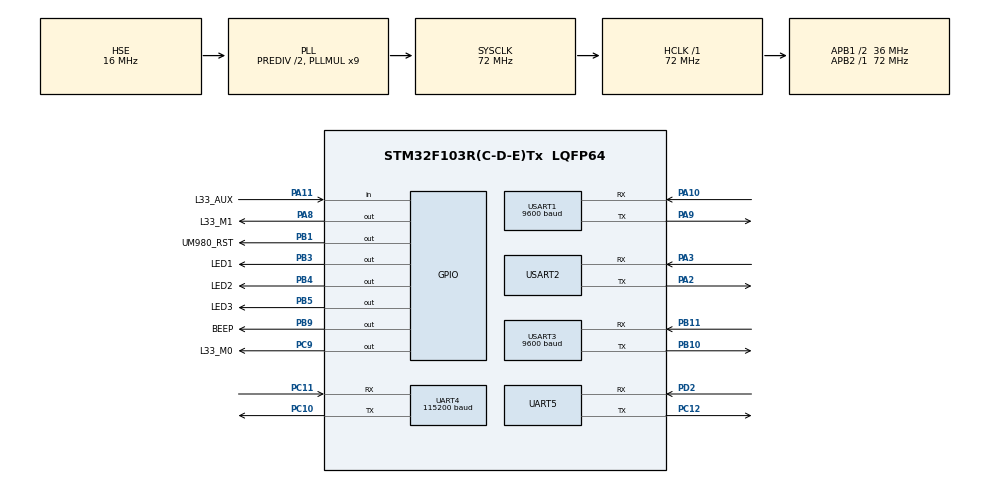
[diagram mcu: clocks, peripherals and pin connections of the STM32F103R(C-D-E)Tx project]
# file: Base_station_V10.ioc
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Dma.Request0=USART1_RX
Dma.Request1=USART1_TX
Dma.Request2=USART2_RX
Dma.Request3=USART2_TX
Dma.Request4=USART3_RX
Dma.Request5=USART3_TX
Dma.Request6=UART4_RX
Dma.Request7=UART4_TX
Dma.UART4_RX.6.Direction=DMA_PERIPH_TO_MEMORY
Dma.UART4_RX.6.Instance=DMA2_Channel3
Dma.UART4_RX.6.MemDataAlignment=DMA_MDATAALIGN_BYTE
Dma.UART4_RX.6.MemInc=DMA_MINC_ENABLE
Dma.UART4_RX.6.Mode=DMA_NORMAL
Dma.UART4_RX.6.PeriphDataAlignment=DMA_PDATAALIGN_BYTE
Dma.UART4_RX.6.PeriphInc=DMA_PINC_DISABLE
Dma.UART4_RX.6.Priority=DMA_PRIORITY_LOW
Dma.UART4_TX.7.Direction=DMA_MEMORY_TO_PERIPH
Dma.UART4_TX.7.Instance=DMA2_Channel5
Dma.UART4_TX.7.MemDataAlignment=DMA_MDATAALIGN_BYTE
Dma.UART4_TX.7.MemInc=DMA_MINC_ENABLE
Dma.UART4_TX.7.Mode=DMA_NORMAL
Dma.UART4_TX.7.PeriphDataAlignment=DMA_PDATAALIGN_BYTE
Dma.UART4_TX.7.PeriphInc=DMA_PINC_DISABLE
Dma.UART4_TX.7.Priority=DMA_PRIORITY_LOW
Dma.USART1_RX.0.Direction=DMA_PERIPH_TO_MEMORY
Dma.USART1_RX.0.Instance=DMA1_Channel5
Dma.USART1_RX.0.MemDataAlignment=DMA_MDATAALIGN_BYTE
Dma.USART1_RX.0.MemInc=DMA_MINC_ENABLE
Dma.USART1_RX.0.Mode=DMA_NORMAL
Dma.USART1_RX.0.PeriphDataAlignment=DMA_PDATAALIGN_BYTE
Dma.USART1_RX.0.PeriphInc=DMA_PINC_DISABLE
Dma.USART1_RX.0.Priority=DMA_PRIORITY_MEDIUM
Dma.USART1_TX.1.Direction=DMA_MEMORY_TO_PERIPH
Dma.USART1_TX.1.Instance=DMA1_Channel4
Dma.USART1_TX.1.MemDataAlignment=DMA_MDATAALIGN_BYTE
Dma.USART1_TX.1.MemInc=DMA_MINC_ENABLE
Dma.USART1_TX.1.Mode=DMA_NORMAL
Dma.USART1_TX.1.PeriphDataAlignment=DMA_PDATAALIGN_BYTE
Dma.USART1_TX.1.PeriphInc=DMA_PINC_DISABLE
Dma.USART1_TX.1.Priority=DMA_PRIORITY_LOW
Dma.USART2_RX.2.Direction=DMA_PERIPH_TO_MEMORY
Dma.USART2_RX.2.Instance=DMA1_Channel6
Dma.USART2_RX.2.MemDataAlignment=DMA_MDATAALIGN_BYTE
Dma.USART2_RX.2.MemInc=DMA_MINC_ENABLE
Dma.USART2_RX.2.Mode=DMA_NORMAL
Dma.USART2_RX.2.PeriphDataAlignment=DMA_PDATAALIGN_BYTE
Dma.USART2_RX.2.PeriphInc=DMA_PINC_DISABLE
Dma.USART2_RX.2.Priority=DMA_PRIORITY_LOW
Dma.USART2_TX.3.Direction=DMA_MEMORY_TO_PERIPH
Dma.USART2_TX.3.Instance=DMA1_Channel7
Dma.USART2_TX.3.MemDataAlignment=DMA_MDATAALIGN_BYTE
Dma.USART2_TX.3.MemInc=DMA_MINC_ENABLE
Dma.USART2_TX.3.Mode=DMA_NORMAL
Dma.USART2_TX.3.PeriphDataAlignment=DMA_PDATAALIGN_BYTE
Dma.USART2_TX.3.PeriphInc=DMA_PINC_DISABLE
Dma.USART2_TX.3.Priority=DMA_PRIORITY_LOW
Dma.USART3_RX.4.Direction=DMA_PERIPH_TO_MEMORY
Dma.USART3_RX.4.Instance=DMA1_Channel3
Dma.USART3_RX.4.MemDataAlignment=DMA_MDATAALIGN_BYTE
Dma.USART3_RX.4.MemInc=DMA_MINC_ENABLE
Dma.USART3_RX.4.Mode=DMA_NORMAL
Dma.USART3_RX.4.PeriphDataAlignment=DMA_PDATAALIGN_BYTE
Dma.USART3_RX.4.PeriphInc=DMA_PINC_DISABLE
Dma.USART3_RX.4.Priority=DMA_PRIORITY_LOW
Dma.USART3_TX.5.Direction=DMA_MEMORY_TO_PERIPH
Dma.USART3_TX.5.Instance=DMA1_Channel2
Dma.USART3_TX.5.MemDataAlignment=DMA_MDATAALIGN_BYTE
Dma.USART3_TX.5.MemInc=DMA_MINC_ENABLE
Dma.USART3_TX.5.Mode=DMA_NORMAL
Dma.USART3_TX.5.PeriphDataAlignment=DMA_PDATAALIGN_BYTE
Dma.USART3_TX.5.PeriphInc=DMA_PINC_DISABLE
Dma.USART3_TX.5.Priority=DMA_PRIORITY_LOW
FREERTOS.BinarySemaphores01=UART1_tx_semaphore,Dynamic,NULL,Available;UART2_tx_semaphore,Dynamic,NULL,Available;UART3_tx_semaphore,Dynamic,NULL,Available;UART4_tx_semaphore,Dynamic,NULL,Available;UART1_rx_semaphore,Dynamic,NULL,Depleted;UART2_rx_semaphore,Dynamic,NULL,Depleted;UART3_rx_semaphore,Dynamic,NULL,Depleted;UART4_rx_semaphore,Dynamic,NULL,Depleted;UART5_tx_semaphore,Dynamic,NULL,Available;UART5_rx_semaphore,Dynamic,NULL,Depleted
FREERTOS.INCLUDE_vTaskDelete=1
FREERTOS.Tasks01=IMU_TASK,24,128,imu_task,As weak,NULL,Dynamic,NULL,NULL;RUN_LED_TASK,17,128,RunLed_task,As weak,NULL,Dynamic,NULL,NULL;RTK_TASK,34,256,RTK_task,As weak,NULL,Dynamic,NULL,NULL;CONSOLE_TASK,8,128,console_task,As weak,NULL,Dynamic,NULL,NULL;LORA_TASK,35,128,LORA_task,As weak,NULL,Dynamic,NULL,NULL
FREERTOS.configTOTAL_HEAP_SIZE=8192
FREERTOS.configUSE_TIMERS=1
Mcu.Family=STM32F1
Mcu.Name=STM32F103R(C-D-E)Tx
Mcu.Package=LQFP64
NVIC.DMA1_Channel2_IRQn=true\:5\:0\:false\:false\:true\:true\:false\:true\:true
NVIC.DMA1_Channel3_IRQn=true\:5\:0\:false\:false\:true\:true\:false\:true\:true
NVIC.DMA1_Channel4_IRQn=true\:5\:0\:false\:false\:true\:true\:false\:true\:true
NVIC.DMA1_Channel5_IRQn=true\:5\:0\:false\:false\:true\:true\:false\:true\:true
NVIC.DMA1_Channel6_IRQn=true\:5\:0\:false\:false\:true\:true\:false\:true\:true
NVIC.DMA1_Channel7_IRQn=true\:5\:0\:false\:false\:true\:true\:false\:true\:true
NVIC.DMA2_Channel3_IRQn=true\:5\:0\:false\:false\:true\:true\:false\:true\:true
NVIC.DMA2_Channel4_5_IRQn=true\:5\:0\:false\:false\:true\:true\:false\:true\:true
NVIC.PriorityGroup=NVIC_PRIORITYGROUP_4
NVIC.TIM2_IRQn=true\:15\:0\:false\:false\:true\:false\:false\:true\:true
NVIC.TimeBase=TIM2_IRQn
NVIC.TimeBaseIP=TIM2
NVIC.UART4_IRQn=true\:5\:0\:false\:false\:true\:true\:true\:true\:true
NVIC.UART5_IRQn=true\:5\:0\:false\:false\:true\:true\:true\:true\:true
NVIC.USART1_IRQn=true\:5\:0\:false\:false\:true\:true\:true\:true\:true
NVIC.USART2_IRQn=true\:5\:0\:false\:false\:true\:true\:true\:true\:true
NVIC.USART3_IRQn=true\:5\:0\:false\:false\:true\:true\:true\:true\:true
PA10.Mode=Asynchronous
PA10.Signal=USART1_RX
PA11.GPIO_Label=L33_AUX
PA11.Signal=GPIO_Input
PA13.Mode=Serial_Wire
PA13.Signal=SYS_JTMS-SWDIO
PA14.Mode=Serial_Wire
PA14.Signal=SYS_JTCK-SWCLK
PA2.Mode=Asynchronous
PA2.Signal=USART2_TX
PA3.Mode=Asynchronous
PA3.Signal=USART2_RX
PA8.GPIO_Label=L33_M1
PA8.Signal=GPIO_Output
PA9.Mode=Asynchronous
PA9.Signal=USART1_TX
PB1.GPIO_Label=UM980_RST
PB1.PinState=GPIO_PIN_SET
PB1.Signal=GPIO_Output
PB10.Mode=Asynchronous
PB10.Signal=USART3_TX
PB11.Mode=Asynchronous
PB11.Signal=USART3_RX
PB3.GPIO_Label=LED1
PB3.PinState=GPIO_PIN_SET
PB3.Signal=GPIO_Output
PB4.GPIO_Label=LED2
PB4.PinState=GPIO_PIN_SET
PB4.Signal=GPIO_Output
PB5.GPIO_Label=LED3
PB5.PinState=GPIO_PIN_SET
PB5.Signal=GPIO_Output
PB9.GPIO_Label=BEEP
PB9.Signal=GPIO_Output
PC10.Mode=Asynchronous
PC10.Signal=UART4_TX
PC11.Mode=Asynchronous
PC11.Signal=UART4_RX
PC12.Mode=Asynchronous
PC12.Signal=UART5_TX
PC9.GPIO_Label=L33_M0
PC9.Signal=GPIO_Output
PD0-OSC_IN.Mode=HSE-External-Oscillator
PD0-OSC_IN.Signal=RCC_OSC_IN
PD1-OSC_OUT.Mode=HSE-External-Oscillator
PD1-OSC_OUT.Signal=RCC_OSC_OUT
PD2.Mode=Asynchronous
PD2.Signal=UART5_RX
ProjectManager.HeapSize=0x400
ProjectManager.StackSize=0x1000
ProjectManager.TargetToolchain=EWARM V8.32
RCC.ADCPresc=RCC_ADCPCLK2_DIV6
RCC.AHBFreq_Value=72000000
RCC.APB1CLKDivider=RCC_HCLK_DIV2
RCC.APB1Freq_Value=36000000
RCC.APB1TimFreq_Value=72000000
RCC.APB2Freq_Value=72000000
RCC.APB2TimFreq_Value=72000000
RCC.HCLKFreq_Value=72000000
RCC.HSEDivPLL=RCC_HSE_PREDIV_DIV2
RCC.HSE_VALUE=16000000
RCC.PLLMUL=RCC_PLL_MUL9
RCC.PLLSourceVirtual=RCC_PLLSOURCE_HSE
RCC.SYSCLKFreq_VALUE=72000000
RCC.SYSCLKSource=RCC_SYSCLKSOURCE_PLLCLK
RCC.USBFreq_Value=72000000
UART4.BaudRate=115200
UART4.VirtualMode=Asynchronous
UART5.VirtualMode=Asynchronous
USART1.BaudRate=9600
USART1.VirtualMode=VM_ASYNC
USART2.VirtualMode=VM_ASYNC
USART3.BaudRate=9600
USART3.VirtualMode=VM_ASYNC
VP_FREERTOS_VS_CMSIS_V2.Mode=CMSIS_V2
VP_SYS_VS_tim2.Mode=TIM2
board=custom

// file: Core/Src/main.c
/* USER CODE BEGIN Header */
/**
  ******************************************************************************
  * @file           : main.c
  * @brief          : Main program body
  ******************************************************************************
  * @attention
  *
  * Copyright (c) 2025 STMicroelectronics.
  * All rights reserved.
  *
  * This software is licensed under terms that can be found in the LICENSE file
  * in the root directory of this software component.
  * If no LICENSE file comes with this software, it is provided AS-IS.
  *
  ******************************************************************************
  */
/* USER CODE END Header */
#include "main.h"
#include "cmsis_os.h"

/* USER CODE BEGIN Includes */
#include "FreeRTOS.h"
#include "queue.h"
#include "passthrough.h"
/* USER CODE END Includes */

UART_HandleTypeDef huart4;
UART_HandleTypeDef huart5;
UART_HandleTypeDef huart1;
UART_HandleTypeDef huart2;
UART_HandleTypeDef huart3;
DMA_HandleTypeDef hdma_uart4_rx;
DMA_HandleTypeDef hdma_uart4_tx;
DMA_HandleTypeDef hdma_usart1_rx;
DMA_HandleTypeDef hdma_usart1_tx;
DMA_HandleTypeDef hdma_usart2_rx;
DMA_HandleTypeDef hdma_usart2_tx;
DMA_HandleTypeDef hdma_usart3_rx;
DMA_HandleTypeDef hdma_usart3_tx;

/* Definitions for IMU_TASK */
osThreadId_t IMU_TASKHandle;
const osThreadAttr_t IMU_TASK_attributes = {
  .name = "IMU_TASK",
  .stack_size = 128 * 4,
  .priority = (osPriority_t) osPriorityNormal,
};
/* Definitions for RUN_LED_TASK */
osThreadId_t RUN_LED_TASKHandle;
const osThreadAttr_t RUN_LED_TASK_attributes = {
  .name = "RUN_LED_TASK",
  .stack_size = 128 * 4,
  .priority = (osPriority_t) osPriorityBelowNormal1,
};
/* Definitions for  PASSTHROUGH_TASK */
osThreadId_t PASSTHROUGH_TASKHandle;
const osThreadAttr_t PASSTHROUGH_TASK_attributes = {
  .name = "PASSTHROUGH",
  .stack_size = 256 * 4,
  .priority = (osPriority_t) osPriorityAboveNormal3,
};
/* Definitions for LORA_TASK */
osThreadId_t LORA_TASKHandle;
const osThreadAttr_t LORA_TASK_attributes = {
  .name = "LORA_TASK",
  .stack_size = 256 * 4,
  .priority = (osPriority_t) osPriorityAboveNormal2,
};
/* Definitions for UART1_tx_semaphore */
osSemaphoreId_t UART1_tx_semaphoreHandle;
const osSemaphoreAttr_t UART1_tx_semaphore_attributes = {
  .name = "UART1_tx_semaphore"
};
/* Definitions for UART2_tx_semaphore */
osSemaphoreId_t UART2_tx_semaphoreHandle;
const osSemaphoreAttr_t UART2_tx_semaphore_attributes = {
  .name = "UART2_tx_semaphore"
};
/* Definitions for UART3_tx_semaphore */
osSemaphoreId_t UART3_tx_semaphoreHandle;
const osSemaphoreAttr_t UART3_tx_semaphore_attributes = {
  .name = "UART3_tx_semaphore"
};
/* Definitions for UART4_tx_semaphore */
osSemaphoreId_t UART4_tx_semaphoreHandle;
const osSemaphoreAttr_t UART4_tx_semaphore_attributes = {
  .name = "UART4_tx_semaphore"
};
/* Definitions for UART1_rx_semaphore */
osSemaphoreId_t UART1_rx_semaphoreHandle;
const osSemaphoreAttr_t UART1_rx_semaphore_attributes = {
  .name = "UART1_rx_semaphore"
};
/* Definitions for UART2_rx_semaphore */
osSemaphoreId_t UART2_rx_semaphoreHandle;
const osSemaphoreAttr_t UART2_rx_semaphore_attributes = {
  .name = "UART2_rx_semaphore"
};
/* Definitions for UART3_rx_semaphore */
osSemaphoreId_t UART3_rx_semaphoreHandle;
const osSemaphoreAttr_t UART3_rx_semaphore_attributes = {
  .name = "UART3_rx_semaphore"
};
/* Definitions for UART4_rx_semaphore */
osSemaphoreId_t UART4_rx_semaphoreHandle;
const osSemaphoreAttr_t UART4_rx_semaphore_attributes = {
  .name = "UART4_rx_semaphore"
};
/* Definitions for UART5_tx_semaphore */
osSemaphoreId_t UART5_tx_semaphoreHandle;
const osSemaphoreAttr_t UART5_tx_semaphore_attributes = {
  .name = "UART5_tx_semaphore"
};
/* Definitions for UART5_rx_semaphore */
osSemaphoreId_t UART5_rx_semaphoreHandle;
const osSemaphoreAttr_t UART5_rx_semaphore_attributes = {
  .name = "UART5_rx_semaphore"
};

void SystemClock_Config(void);
static void MX_GPIO_Init(void);
static void MX_DMA_Init(void);
static void MX_USART1_UART_Init(void);
static void MX_UART4_Init(void);
static void MX_UART5_Init(void);
static void MX_USART2_UART_Init(void);
static void MX_USART3_UART_Init(void);
void imu_task(void *argument);
void RunLed_task(void *argument);
void passthrough_task(void *argument);
void LORA_task(void *argument);

int main(void)
{

  /* MCU Configuration--------------------------------------------------------*/

  /* Reset of all peripherals, Initializes the Flash interface and the Systick. */
  HAL_Init();

  /* Configure the system clock */
  SystemClock_Config();

  /* Initialize all configured peripherals */
  MX_GPIO_Init();
  MX_DMA_Init();
  MX_USART1_UART_Init();
  MX_UART4_Init();
  MX_UART5_Init();
  MX_USART2_UART_Init();
  MX_USART3_UART_Init();

  /* Init scheduler */
  osKernelInitialize();

  /* USER CODE BEGIN RTOS_MUTEX */
  /* add mutexes, ... */
  /* g_rtcm_mutex kept for LORA_task to read RTCM */
  extern osMutexId g_rtcm_mutex;
  g_rtcm_mutex = osMutexNew(NULL);
  /* USER CODE END RTOS_MUTEX */

  /* Create the semaphores(s) */
  /* creation of UART1_tx_semaphore */
  UART1_tx_semaphoreHandle = osSemaphoreNew(1, 1, &UART1_tx_semaphore_attributes);

  /* creation of UART2_tx_semaphore */
  UART2_tx_semaphoreHandle = osSemaphoreNew(1, 1, &UART2_tx_semaphore_attributes);

  /* creation of UART3_tx_semaphore */
  UART3_tx_semaphoreHandle = osSemaphoreNew(1, 1, &UART3_tx_semaphore_attributes);

  /* creation of UART4_tx_semaphore */
  UART4_tx_semaphoreHandle = osSemaphoreNew(1, 1, &UART4_tx_semaphore_attributes);

  /* creation of UART1_rx_semaphore */
  UART1_rx_semaphoreHandle = osSemaphoreNew(1, 0, &UART1_rx_semaphore_attributes);

  /* creation of UART2_rx_semaphore */
  UART2_rx_semaphoreHandle = osSemaphoreNew(1, 0, &UART2_rx_semaphore_attributes);

  /* creation of UART3_rx_semaphore */
  UART3_rx_semaphoreHandle = osSemaphoreNew(1, 0, &UART3_rx_semaphore_attributes);

  /* creation of UART4_rx_semaphore */
  UART4_rx_semaphoreHandle = osSemaphoreNew(1, 0, &UART4_rx_semaphore_attributes);

  /* creation of UART5_tx_semaphore */
  UART5_tx_semaphoreHandle = osSemaphoreNew(1, 1, &UART5_tx_semaphore_attributes);

  /* creation of UART5_rx_semaphore */
  UART5_rx_semaphoreHandle = osSemaphoreNew(1, 0, &UART5_rx_semaphore_attributes);

  /* Create the thread(s) */
  /* creation of IMU_TASK */
  IMU_TASKHandle = osThreadNew(imu_task, NULL, &IMU_TASK_attributes);

  /* creation of RUN_LED_TASK */
  RUN_LED_TASKHandle = osThreadNew(RunLed_task, NULL, &RUN_LED_TASK_attributes);

  /* creation of PASSTHROUGH_TASK - UART5<->UART4 bridge */
  PASSTHROUGH_TASKHandle = osThreadNew(passthrough_task, NULL, &PASSTHROUGH_TASK_attributes);

  /* creation of LORA_TASK - RTCM over LoRa (keep as-is) */
  LORA_TASKHandle = osThreadNew(LORA_task, NULL, &LORA_TASK_attributes);

  /* Start scheduler */
  osKernelStart();

  /* We should never get here as control is now taken by the scheduler */

  /* Infinite loop */
  while (1)
  {

  }
}

void SystemClock_Config(void)
{
  RCC_OscInitTypeDef RCC_OscInitStruct = {0};
  RCC_ClkInitTypeDef RCC_ClkInitStruct = {0};

  /** Initializes the RCC Oscillators according to the specified parameters
  * in the RCC_OscInitTypeDef structure.
  */
  RCC_OscInitStruct.OscillatorType = RCC_OSCILLATORTYPE_HSE;
  RCC_OscInitStruct.HSEState = RCC_HSE_ON;
  RCC_OscInitStruct.HSEPredivValue = RCC_HSE_PREDIV_DIV2;
  RCC_OscInitStruct.HSIState = RCC_HSI_ON;
  RCC_OscInitStruct.PLL.PLLState = RCC_PLL_ON;
  RCC_OscInitStruct.PLL.PLLSource = RCC_PLLSOURCE_HSE;
  RCC_OscInitStruct.PLL.PLLMUL = RCC_PLL_MUL9;
  if (HAL_RCC_OscConfig(&RCC_OscInitStruct) != HAL_OK)
  {
    Error_Handler();
  }

  /** Initializes the CPU, AHB and APB buses clocks
  */
  RCC_ClkInitStruct.ClockType = RCC_CLOCKTYPE_HCLK|RCC_CLOCKTYPE_SYSCLK
                              |RCC_CLOCKTYPE_PCLK1|RCC_CLOCKTYPE_PCLK2;
  RCC_ClkInitStruct.SYSCLKSource = RCC_SYSCLKSOURCE_PLLCLK;
  RCC_ClkInitStruct.AHBCLKDivider = RCC_SYSCLK_DIV1;
  RCC_ClkInitStruct.APB1CLKDivider = RCC_HCLK_DIV2;
  RCC_ClkInitStruct.APB2CLKDivider = RCC_HCLK_DIV1;

  if (HAL_RCC_ClockConfig(&RCC_ClkInitStruct, FLASH_LATENCY_2) != HAL_OK)
  {
    Error_Handler();
  }
}

static void MX_UART4_Init(void)
{

  huart4.Instance = UART4;
  huart4.Init.BaudRate = 115200;
  huart4.Init.WordLength = UART_WORDLENGTH_8B;
  huart4.Init.StopBits = UART_STOPBITS_1;
  huart4.Init.Parity = UART_PARITY_NONE;
  huart4.Init.Mode = UART_MODE_TX_RX;
  huart4.Init.HwFlowCtl = UART_HWCONTROL_NONE;
  huart4.Init.OverSampling = UART_OVERSAMPLING_16;
  if (HAL_UART_Init(&huart4) != HAL_OK)
  {
    Error_Handler();
  }

}

static void MX_UART5_Init(void)
{

  huart5.Instance = UART5;
  huart5.Init.BaudRate = 115200;
  huart5.Init.WordLength = UART_WORDLENGTH_8B;
  huart5.Init.StopBits = UART_STOPBITS_1;
  huart5.Init.Parity = UART_PARITY_NONE;
  huart5.Init.Mode = UART_MODE_TX_RX;
  huart5.Init.HwFlowCtl = UART_HWCONTROL_NONE;
  huart5.Init.OverSampling = UART_OVERSAMPLING_16;
  if (HAL_UART_Init(&huart5) != HAL_OK)
  {
    Error_Handler();
  }

}

static void MX_USART1_UART_Init(void)
{

  huart1.Instance = USART1;
  huart1.Init.BaudRate = 115200;
  huart1.Init.WordLength = UART_WORDLENGTH_8B;
  huart1.Init.StopBits = UART_STOPBITS_1;
  huart1.Init.Parity = UART_PARITY_NONE;
  huart1.Init.Mode = UART_MODE_TX_RX;
  huart1.Init.HwFlowCtl = UART_HWCONTROL_NONE;
  huart1.Init.OverSampling = UART_OVERSAMPLING_16;
  if (HAL_UART_Init(&huart1) != HAL_OK)
  {
    Error_Handler();
  }

}

static void MX_USART2_UART_Init(void)
{

  huart2.Instance = USART2;
  huart2.Init.BaudRate = 115200;
  huart2.Init.WordLength = UART_WORDLENGTH_8B;
  huart2.Init.StopBits = UART_STOPBITS_1;
  huart2.Init.Parity = UART_PARITY_NONE;
  huart2.Init.Mode = UART_MODE_TX_RX;
  huart2.Init.HwFlowCtl = UART_HWCONTROL_NONE;
  huart2.Init.OverSampling = UART_OVERSAMPLING_16;
  if (HAL_UART_Init(&huart2) != HAL_OK)
  {
    Error_Handler();
  }

}

static void MX_USART3_UART_Init(void)
{

  huart3.Instance = USART3;
  huart3.Init.BaudRate = 115200;
  huart3.Init.WordLength = UART_WORDLENGTH_8B;
  huart3.Init.StopBits = UART_STOPBITS_1;
  huart3.Init.Parity = UART_PARITY_NONE;
  huart3.Init.Mode = UART_MODE_TX_RX;
  huart3.Init.HwFlowCtl = UART_HWCONTROL_NONE;
  huart3.Init.OverSampling = UART_OVERSAMPLING_16;
  if (HAL_UART_Init(&huart3) != HAL_OK)
  {
    Error_Handler();
  }

}

static void MX_DMA_Init(void)
{

  /* DMA controller clock enable */
  __HAL_RCC_DMA1_CLK_ENABLE();
  __HAL_RCC_DMA2_CLK_ENABLE();

  /* DMA interrupt init */
  /* DMA1_Channel2_IRQn interrupt configuration */
  HAL_NVIC_SetPriority(DMA1_Channel2_IRQn, 5, 0);
  HAL_NVIC_EnableIRQ(DMA1_Channel2_IRQn);
  /* DMA1_Channel3_IRQn interrupt configuration */
  HAL_NVIC_SetPriority(DMA1_Channel3_IRQn, 5, 0);
  HAL_NVIC_EnableIRQ(DMA1_Channel3_IRQn);
  /* DMA1_Channel4_IRQn interrupt configuration */
  HAL_NVIC_SetPriority(DMA1_Channel4_IRQn, 5, 0);
  HAL_NVIC_EnableIRQ(DMA1_Channel4_IRQn);
  /* DMA1_Channel5_IRQn interrupt configuration */
  HAL_NVIC_SetPriority(DMA1_Channel5_IRQn, 5, 0);
  HAL_NVIC_EnableIRQ(DMA1_Channel5_IRQn);
  /* DMA1_Channel6_IRQn interrupt configuration */
  HAL_NVIC_SetPriority(DMA1_Channel6_IRQn, 5, 0);
  HAL_NVIC_EnableIRQ(DMA1_Channel6_IRQn);
  /* DMA1_Channel7_IRQn interrupt configuration */
  HAL_NVIC_SetPriority(DMA1_Channel7_IRQn, 5, 0);
  HAL_NVIC_EnableIRQ(DMA1_Channel7_IRQn);
  /* DMA2_Channel3_IRQn interrupt configuration */
  HAL_NVIC_SetPriority(DMA2_Channel3_IRQn, 5, 0);
  HAL_NVIC_EnableIRQ(DMA2_Channel3_IRQn);
  /* DMA2_Channel4_5_IRQn interrupt configuration */
  HAL_NVIC_SetPriority(DMA2_Channel4_5_IRQn, 5, 0);
  HAL_NVIC_EnableIRQ(DMA2_Channel4_5_IRQn);

}

static void MX_GPIO_Init(void)
{
  GPIO_InitTypeDef GPIO_InitStruct = {0};

  /* GPIO Ports Clock Enable */
  __HAL_RCC_GPIOD_CLK_ENABLE();
  __HAL_RCC_GPIOA_CLK_ENABLE();
  __HAL_RCC_GPIOB_CLK_ENABLE();
  __HAL_RCC_GPIOC_CLK_ENABLE();

  /*Configure GPIO pin Output Level */
  HAL_GPIO_WritePin(GPIOB, UM980_RST_Pin|LED1_Pin|LED2_Pin|LED3_Pin, GPIO_PIN_SET);

  /*Configure GPIO pin Output Level */
  HAL_GPIO_WritePin(L33_M0_GPIO_Port, L33_M0_Pin, GPIO_PIN_RESET);

  /*Configure GPIO pin Output Level */
  HAL_GPIO_WritePin(L33_M1_GPIO_Port, L33_M1_Pin, GPIO_PIN_RESET);

  /*Configure GPIO pin Output Level */
  HAL_GPIO_WritePin(BEEP_GPIO_Port, BEEP_Pin, GPIO_PIN_RESET);

  /*Configure GPIO pins : UM980_RST_Pin LED1_Pin LED2_Pin LED3_Pin
                           BEEP_Pin */
  GPIO_InitStruct.Pin = UM980_RST_Pin|LED1_Pin|LED2_Pin|LED3_Pin
                          |BEEP_Pin;
  GPIO_InitStruct.Mode = GPIO_MODE_OUTPUT_PP;
  GPIO_InitStruct.Pull = GPIO_NOPULL;
  GPIO_InitStruct.Speed = GPIO_SPEED_FREQ_LOW;
  HAL_GPIO_Init(GPIOB, &GPIO_InitStruct);

  /*Configure GPIO pin : L33_M0_Pin */
  GPIO_InitStruct.Pin = L33_M0_Pin;
  GPIO_InitStruct.Mode = GPIO_MODE_OUTPUT_PP;
  GPIO_InitStruct.Pull = GPIO_NOPULL;
  GPIO_InitStruct.Speed = GPIO_SPEED_FREQ_LOW;
  HAL_GPIO_Init(L33_M0_GPIO_Port, &GPIO_InitStruct);

  /*Configure GPIO pin : L33_M1_Pin */
  GPIO_InitStruct.Pin = L33_M1_Pin;
  GPIO_InitStruct.Mode = GPIO_MODE_OUTPUT_PP;
  GPIO_InitStruct.Pull = GPIO_NOPULL;
  GPIO_InitStruct.Speed = GPIO_SPEED_FREQ_LOW;
  HAL_GPIO_Init(L33_M1_GPIO_Port, &GPIO_InitStruct);

  /*Configure GPIO pin : L33_AUX_Pin */
  GPIO_InitStruct.Pin = L33_AUX_Pin;
  GPIO_InitStruct.Mode = GPIO_MODE_INPUT;
  GPIO_InitStruct.Pull = GPIO_NOPULL;
  HAL_GPIO_Init(L33_AUX_GPIO_Port, &GPIO_InitStruct);

}

__weak void imu_task(void *argument)
{
  for(;;)
  {
    osDelay(1);
  }
}

__weak void RunLed_task(void *argument)
{
  for(;;)
  {
    osDelay(1);
  }
}

/* USER CODE BEGIN Header_RTK_task */
/**
* @brief Function implementing the RTK_TASK thread - now passthrough
* @param argument: Not used
* @retval None
*/
/* USER CODE END Header_RTK_task */
__weak void RTK_task(void *argument)
{
  for(;;)
  {
    osDelay(1);
  }
}

__weak void LORA_task(void *argument)
{
  for(;;)
  {
    osDelay(1);
  }
}

void HAL_TIM_PeriodElapsedCallback(TIM_HandleTypeDef *htim)
{
  if (htim->Instance == TIM2)
  {
    HAL_IncTick();
  }
}

void Error_Handler(void)
{
  __disable_irq();
  while (1)
  {
  }
}
